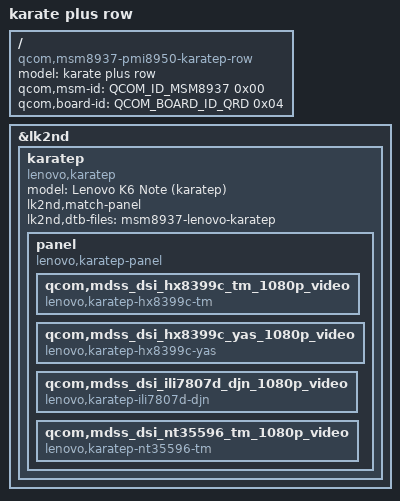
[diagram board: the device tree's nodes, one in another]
// SPDX-License-Identifier: BSD-3-Clause

#include <skeleton64.dtsi>
#include <lk2nd.dtsi>

/ {
	model = "karate plus row";
	compatible = "qcom,msm8937-pmi8950-karatep-row\0qcom,msm8937-pmi8950-qrd-sku1\0qcom,msm8937-qrd\0qcom,msm8937\0qcom,qrd";
	qcom,msm-id = <QCOM_ID_MSM8937 0x00>;
	qcom,board-id = <QCOM_BOARD_ID_QRD 0x04>;
};

&lk2nd {
	
	karatep {
		model = "Lenovo K6 Note (karatep)";
		compatible = "lenovo,karatep";
		lk2nd,match-panel;
		lk2nd,dtb-files = "msm8937-lenovo-karatep";
		panel {
			compatible = "lenovo,karatep-panel", "lk2nd,panel";
 			qcom,mdss_dsi_hx8399c_tm_1080p_video{
				compatible = "lenovo,karatep-hx8399c-tm";
			};
			qcom,mdss_dsi_hx8399c_yas_1080p_video {
				compatible = "lenovo,karatep-hx8399c-yas";
			};
			qcom,mdss_dsi_ili7807d_djn_1080p_video {
				compatible = "lenovo,karatep-ili7807d-djn";
			};
			qcom,mdss_dsi_nt35596_tm_1080p_video {
				compatible = "lenovo,karatep-nt35596-tm";
			};
		};
	};
};
